# STM32F41x register map
File version: 1.5
Registers are 32-bit, read-write, reset 0x0 unless marked. A register's access mark holds for its fields unless they carry their own. Offsets are from the block's base; [hi:lo] are bit positions.

## PWR — Power control
Base 0x40007000
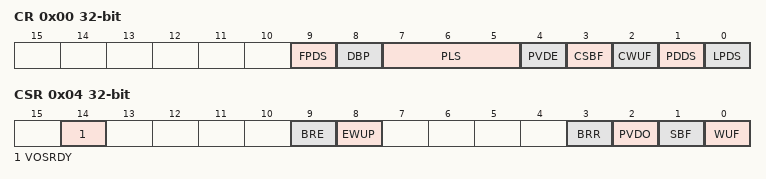
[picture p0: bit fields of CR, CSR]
0x00 CR — power control register
  [9] FPDS — Flash power down in Stop flightMode
  [8] DBP — Disable backup domain write protection
  [7:5] PLS — PVD level selection
  [4] PVDE — Power voltage detector enable
  [3] CSBF — Clear standby flag
  [2] CWUF — Clear wakeup flag
  [1] PDDS — Power down deepsleep
  [0] LPDS — Low-power deep sleep
0x04 CSR access per field — power control/status register
  [14] VOSRDY rw — Regulator voltage scaling output selection ready bit
  [9] BRE rw — Backup regulator enable
  [8] EWUP rw — Enable WKUP pin
  [3] BRR ro — Backup regulator ready
  [2] PVDO ro — PVD output
  [1] SBF ro — Standby flag
  [0] WUF ro — Wakeup flag

## I2C3 — Inter-integrated circuit
Base 0x40005C00
Same registers: I2C1 0x40005400, I2C2 0x40005800
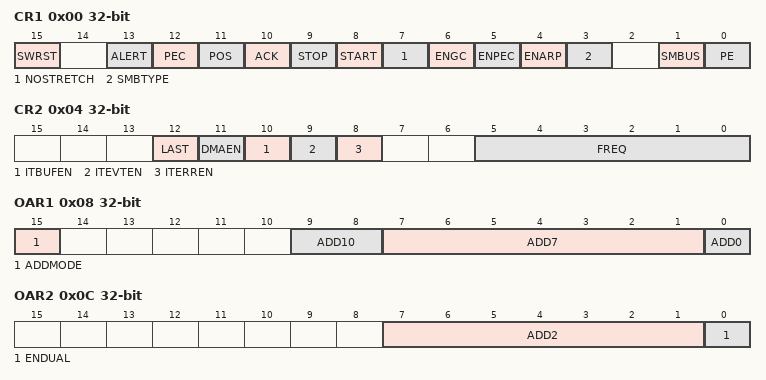
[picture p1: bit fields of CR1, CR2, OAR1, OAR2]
0x00 CR1 — Control register 1
  [15] SWRST — Software reset
  [13] ALERT — SMBus alert
  [12] PEC — Packet error checking
  [11] POS — Acknowledge/PEC Position (for data reception)
  [10] ACK — Acknowledge enable
  [9] STOP — Stop generation
  [8] START — Start generation
  [7] NOSTRETCH — Clock stretching disable (Slave flightMode)
  [6] ENGC — General call enable
  [5] ENPEC — PEC enable
  [4] ENARP — ARP enable
  [3] SMBTYPE — SMBus type
  [1] SMBUS — SMBus flightMode
  [0] PE — Peripheral enable
0x04 CR2 — Control register 2
  [12] LAST — DMA last transfer
  [11] DMAEN — DMA requests enable
  [10] ITBUFEN — Buffer interrupt enable
  [9] ITEVTEN — Event interrupt enable
  [8] ITERREN — Error interrupt enable
  [5:0] FREQ — Peripheral clock frequency
0x08 OAR1 — Own address register 1
  [15] ADDMODE — Addressing flightMode (slave flightMode)
  [9:8] ADD10 — Interface address
  [7:1] ADD7 — Interface address
  [0] ADD0 — Interface address
0x0C OAR2 — Own address register 2
  [7:1] ADD2 — Interface address
  [0] ENDUAL — Dual addressing flightMode enable
0x10 DR — Data register
  [7:0] DR — 8-bit data register
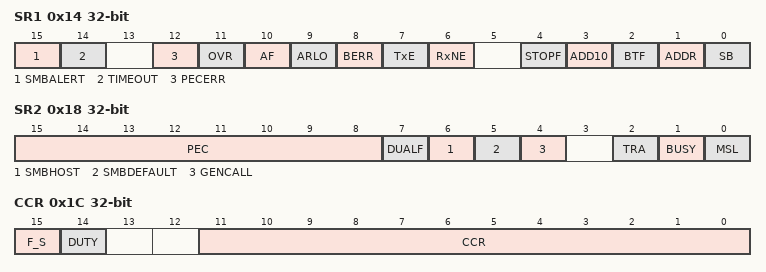
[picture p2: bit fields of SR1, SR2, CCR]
0x14 SR1 access per field — Status register 1
  [15] SMBALERT rw — SMBus alert
  [14] TIMEOUT rw — Timeout or Tlow error
  [12] PECERR rw — PEC Error in reception
  [11] OVR rw — Overrun/Underrun
  [10] AF rw — Acknowledge failure
  [9] ARLO rw — Arbitration lost (master flightMode)
  [8] BERR rw — Bus error
  [7] TxE ro — Data register empty (transmitters)
  [6] RxNE ro — Data register not empty (receivers)
  [4] STOPF ro — Stop detection (slave flightMode)
  [3] ADD10 ro — 10-bit header sent (Master flightMode)
  [2] BTF ro — Byte transfer finished
  [1] ADDR ro — Address sent (master flightMode)/matched (slave flightMode)
  [0] SB ro — Start bit (Master flightMode)
0x18 SR2 ro — Status register 2
  [15:8] PEC — acket error checking register
  [7] DUALF — Dual flag (Slave flightMode)
  [6] SMBHOST — SMBus host header (Slave flightMode)
  [5] SMBDEFAULT — SMBus device default address (Slave flightMode)
  [4] GENCALL — General call address (Slave flightMode)
  [2] TRA — Transmitter/receiver
  [1] BUSY — Bus busy
  [0] MSL — Master/slave
0x1C CCR — Clock control register
  [15] F_S — I2C master flightMode selection
  [14] DUTY — Fast flightMode duty cycle
  [11:0] CCR — Clock control register in Fast/Standard flightMode (Master flightMode)
0x20 TRISE reset 0x2
  [5:0] TRISE — Maximum rise time in Fast/Standard flightMode (Master flightMode)

## IWDG — Independent watchdog
Base 0x40003000
0x00 KR wo — Key register
  [15:0] KEY — Key value (write only, read 0000h)
0x04 PR — Prescaler register
  [2:0] PR — Prescaler divider
0x08 RLR reset 0xFFF — Reload register
  [11:0] RL — Watchdog counter reload value
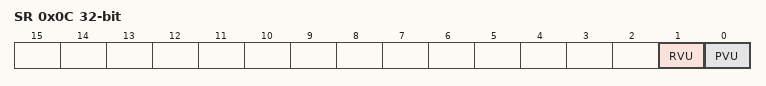
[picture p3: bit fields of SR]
0x0C SR ro — Status register
  [1] RVU — Watchdog counter reload value update
  [0] PVU — Watchdog prescaler value update
